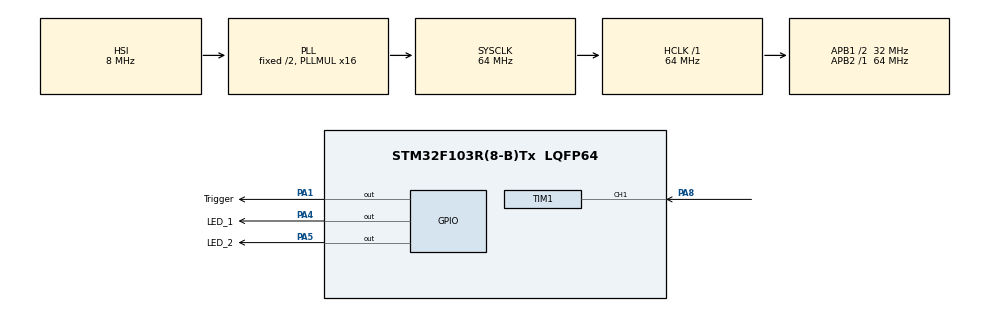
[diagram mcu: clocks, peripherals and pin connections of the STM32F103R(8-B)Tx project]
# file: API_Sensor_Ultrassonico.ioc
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Mcu.Family=STM32F1
Mcu.Name=STM32F103R(8-B)Tx
Mcu.Package=LQFP64
NVIC.PriorityGroup=NVIC_PRIORITYGROUP_4
NVIC.TIM1_CC_IRQn=true\:0\:0\:false\:false\:true\:true\:true\:true
NVIC.TIM3_IRQn=true\:0\:0\:false\:false\:true\:true\:true\:true
PA1.GPIO_Label=Trigger
PA1.Signal=GPIO_Output
PA4.GPIO_Label=LED_1
PA4.Signal=GPIO_Output
PA5.GPIO_Label=LED_2
PA5.Signal=GPIO_Output
PA8.Signal=S_TIM1_CH1
ProjectManager.HeapSize=0x200
ProjectManager.StackSize=0x400
ProjectManager.TargetToolchain=STM32CubeIDE
RCC.AHBFreq_Value=64000000
RCC.APB1CLKDivider=RCC_HCLK_DIV2
RCC.APB1Freq_Value=32000000
RCC.APB1TimFreq_Value=64000000
RCC.APB2Freq_Value=64000000
RCC.APB2TimFreq_Value=64000000
RCC.HCLKFreq_Value=64000000
RCC.PLLMUL=RCC_PLL_MUL16
RCC.SYSCLKFreq_VALUE=64000000
RCC.SYSCLKSource=RCC_SYSCLKSOURCE_PLLCLK
RCC.USBFreq_Value=64000000
SH.S_TIM1_CH1.0=TIM1_CH1,Input_Capture1_from_TI1
TIM1.Channel-Input_Capture1_from_TI1=TIM_CHANNEL_1
TIM1.Period=0xffff - 1
TIM1.Prescaler=64-1
TIM3.Prescaler=64-1
VP_TIM1_VS_ClockSourceINT.Mode=Internal
VP_TIM3_VS_ClockSourceINT.Mode=Internal
board=custom

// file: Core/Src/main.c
/* USER CODE BEGIN Header */
/**
  ******************************************************************************
  * @file           : main.c
  * @brief          : Main program body
  ******************************************************************************
  * @attention
  *
  * Copyright (c) 2022 STMicroelectronics.
  * All rights reserved.
  *
  * This software is licensed under terms that can be found in the LICENSE file
  * in the root directory of this software component.
  * If no LICENSE file comes with this software, it is provided AS-IS.
  *
  ******************************************************************************
  */
/* USER CODE END Header */
#include "main.h"
#include "Ultrassonico.h"

TIM_HandleTypeDef htim1;
TIM_HandleTypeDef htim3;

/* USER CODE BEGIN PV */
TIM_HandleTypeDef htim1;
TIM_HandleTypeDef htim3;
/* USER CODE END PV */

void SystemClock_Config(void);
static void MX_GPIO_Init(void);
static void MX_TIM1_Init(void);
static void MX_TIM3_Init(void);

int main(void)
{

  /* MCU Configuration--------------------------------------------------------*/

  /* Reset of all peripherals, Initializes the Flash interface and the Systick. */
  HAL_Init();

  /* Configure the system clock */
  SystemClock_Config();

  /* USER CODE BEGIN SysInit */
  HAL_TIM_Base_Start(&htim3);
  /* USER CODE END SysInit */

  /* Initialize all configured peripherals */
  MX_GPIO_Init();
  MX_TIM1_Init();
  MX_TIM3_Init();
HAL_TIM_IC_Start_IT(&htim1, TIM_CHANNEL_1);
  /* Infinite loop */
  while (1)
  {
Aproximacao();
  }
}

void SystemClock_Config(void)
{
  RCC_OscInitTypeDef RCC_OscInitStruct = {0};
  RCC_ClkInitTypeDef RCC_ClkInitStruct = {0};

  /** Initializes the RCC Oscillators according to the specified parameters
  * in the RCC_OscInitTypeDef structure.
  */
  RCC_OscInitStruct.OscillatorType = RCC_OSCILLATORTYPE_HSI;
  RCC_OscInitStruct.HSIState = RCC_HSI_ON;
  RCC_OscInitStruct.HSICalibrationValue = RCC_HSICALIBRATION_DEFAULT;
  RCC_OscInitStruct.PLL.PLLState = RCC_PLL_ON;
  RCC_OscInitStruct.PLL.PLLSource = RCC_PLLSOURCE_HSI_DIV2;
  RCC_OscInitStruct.PLL.PLLMUL = RCC_PLL_MUL16;
  if (HAL_RCC_OscConfig(&RCC_OscInitStruct) != HAL_OK)
  {
    Error_Handler();
  }

  /** Initializes the CPU, AHB and APB buses clocks
  */
  RCC_ClkInitStruct.ClockType = RCC_CLOCKTYPE_HCLK|RCC_CLOCKTYPE_SYSCLK
                              |RCC_CLOCKTYPE_PCLK1|RCC_CLOCKTYPE_PCLK2;
  RCC_ClkInitStruct.SYSCLKSource = RCC_SYSCLKSOURCE_PLLCLK;
  RCC_ClkInitStruct.AHBCLKDivider = RCC_SYSCLK_DIV1;
  RCC_ClkInitStruct.APB1CLKDivider = RCC_HCLK_DIV2;
  RCC_ClkInitStruct.APB2CLKDivider = RCC_HCLK_DIV1;

  if (HAL_RCC_ClockConfig(&RCC_ClkInitStruct, FLASH_LATENCY_2) != HAL_OK)
  {
    Error_Handler();
  }
}

static void MX_TIM1_Init(void)
{

  TIM_ClockConfigTypeDef sClockSourceConfig = {0};
  TIM_MasterConfigTypeDef sMasterConfig = {0};
  TIM_IC_InitTypeDef sConfigIC = {0};

  htim1.Instance = TIM1;
  htim1.Init.Prescaler = 64-1;
  htim1.Init.CounterMode = TIM_COUNTERMODE_UP;
  htim1.Init.Period = 0xffff - 1;
  htim1.Init.ClockDivision = TIM_CLOCKDIVISION_DIV1;
  htim1.Init.RepetitionCounter = 0;
  htim1.Init.AutoReloadPreload = TIM_AUTORELOAD_PRELOAD_DISABLE;
  if (HAL_TIM_Base_Init(&htim1) != HAL_OK)
  {
    Error_Handler();
  }
  sClockSourceConfig.ClockSource = TIM_CLOCKSOURCE_INTERNAL;
  if (HAL_TIM_ConfigClockSource(&htim1, &sClockSourceConfig) != HAL_OK)
  {
    Error_Handler();
  }
  if (HAL_TIM_IC_Init(&htim1) != HAL_OK)
  {
    Error_Handler();
  }
  sMasterConfig.MasterOutputTrigger = TIM_TRGO_RESET;
  sMasterConfig.MasterSlaveMode = TIM_MASTERSLAVEMODE_DISABLE;
  if (HAL_TIMEx_MasterConfigSynchronization(&htim1, &sMasterConfig) != HAL_OK)
  {
    Error_Handler();
  }
  sConfigIC.ICPolarity = TIM_INPUTCHANNELPOLARITY_RISING;
  sConfigIC.ICSelection = TIM_ICSELECTION_DIRECTTI;
  sConfigIC.ICPrescaler = TIM_ICPSC_DIV1;
  sConfigIC.ICFilter = 0;
  if (HAL_TIM_IC_ConfigChannel(&htim1, &sConfigIC, TIM_CHANNEL_1) != HAL_OK)
  {
    Error_Handler();
  }
  /* USER CODE BEGIN TIM1_Init 2 */
  HAL_TIM_Base_Start(&htim1);
  /* USER CODE END TIM1_Init 2 */

}

static void MX_TIM3_Init(void)
{

  TIM_ClockConfigTypeDef sClockSourceConfig = {0};
  TIM_MasterConfigTypeDef sMasterConfig = {0};

  htim3.Instance = TIM3;
  htim3.Init.Prescaler = 64-1;
  htim3.Init.CounterMode = TIM_COUNTERMODE_UP;
  htim3.Init.Period = 65535;
  htim3.Init.ClockDivision = TIM_CLOCKDIVISION_DIV1;
  htim3.Init.AutoReloadPreload = TIM_AUTORELOAD_PRELOAD_DISABLE;
  if (HAL_TIM_Base_Init(&htim3) != HAL_OK)
  {
    Error_Handler();
  }
  sClockSourceConfig.ClockSource = TIM_CLOCKSOURCE_INTERNAL;
  if (HAL_TIM_ConfigClockSource(&htim3, &sClockSourceConfig) != HAL_OK)
  {
    Error_Handler();
  }
  sMasterConfig.MasterOutputTrigger = TIM_TRGO_RESET;
  sMasterConfig.MasterSlaveMode = TIM_MASTERSLAVEMODE_DISABLE;
  if (HAL_TIMEx_MasterConfigSynchronization(&htim3, &sMasterConfig) != HAL_OK)
  {
    Error_Handler();
  }

}

static void MX_GPIO_Init(void)
{
  GPIO_InitTypeDef GPIO_InitStruct = {0};

  /* GPIO Ports Clock Enable */
  __HAL_RCC_GPIOA_CLK_ENABLE();

  /*Configure GPIO pin Output Level */
  HAL_GPIO_WritePin(GPIOA, Trigger_Pin|LED_1_Pin|LED_2_Pin, GPIO_PIN_RESET);

  /*Configure GPIO pins : Trigger_Pin LED_1_Pin LED_2_Pin */
  GPIO_InitStruct.Pin = Trigger_Pin|LED_1_Pin|LED_2_Pin;
  GPIO_InitStruct.Mode = GPIO_MODE_OUTPUT_PP;
  GPIO_InitStruct.Pull = GPIO_NOPULL;
  GPIO_InitStruct.Speed = GPIO_SPEED_FREQ_LOW;
  HAL_GPIO_Init(GPIOA, &GPIO_InitStruct);

}

void Error_Handler(void)
{
  __disable_irq();
  while (1)
  {
  }
}
